# R7FA2E2A7 register map
Vendor: Renesas Electronics Corporation; Series: RA2; File version: 1.50.00
CPU: CM23 r1p0, little endian, MPU, no FPU, VTOR, 2 interrupt priority bits, 32 interrupts
Registers are 32-bit, read-write, reset 0x0 unless marked. A register's access mark holds for its fields unless they carry their own. Offsets are from the block's base; [hi:lo] are bit positions; {n}, {i} and the like mark numbered series; 'fields as' and 'values as' point back to an identical list.

## ELC — Event Link Controller
Base 0x40041000
0x00 ELCR 8-bit — Event Link Controller Register
  [7] ELCON — All Event Link Enable
    0=ELC function is disabled; 1=ELC function is enabled
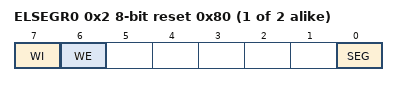
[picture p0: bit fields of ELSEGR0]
{0x2+2i} ELSEGR{i} (i=0..1) 8-bit reset 0x80 — Event Link Software Event Generation Register {i}
  [7] WI wo — ELSEGR Register Write Disable
    0=Write to ELSEGR register enabled; 1=Write to ELSEGR register disabled
  [6] WE — SEG Bit Write Enable
    0=Write to SEG bit disabled; 1=Write to SEG bit enabled
  [0] SEG wo — Software Event Generation
    0=Normal operation; 1=Software event is generated
{0x10+4i} ELSR{i} (i=0..3) 16-bit — Event Link Setting Register {i}
  [7:0] ELS — Event Link Select
{0x10+4i} ELSR{i} (i=8..9) 16-bit — Event Link Setting Register {i}
  [7:0] ELS — Event Link Select
{0x10+4i} ELSR{i} (i=14..15) 16-bit — Event Link Setting Register {i}
  [7:0] ELS — Event Link Select

## POEG — Port Output Enable Module for GPT
Base 0x40042000
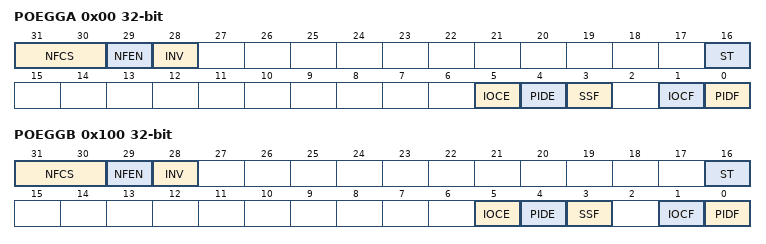
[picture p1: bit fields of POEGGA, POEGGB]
0x00 POEGGA — POEG Group A Setting Register
  [31:30] NFCS — Noise Filter Clock Select
    0=Sample GTETRGn pin input level three times every PCLKB; 1=Sample GTETRGn pin input level three times every PCLKB/8; 2=Sample GTETRGn pin input level three times every PCLKB/32; 3=Sample GTETRGn pin input level three times every PCLKB/128
  [29] NFEN — Noise Filter Enable
    0=Disable noise filtering; 1=Enable noise filtering
  [28] INV — GTETRGA Input Reverse
    0=Input GTETRGn as-is; 1=Input GTETRGn in reverse
  [16] ST ro — GTETRGA Input Status Flag
    0=GTETRGn input after filtering was 0; 1=GTETRGn input after filtering was 1
  [5] IOCE — Enable for GPT Output-Disable Request
    0=Disable output-disable requests from GPT; 1=Enable output-disable requests from GPT
  [4] PIDE — Port Input Detection Enable
    0=Disable output-disable requests from the GTETRGn pins; 1=Enable output-disable requests from the GTETRGn pins
  [3] SSF — Software Stop Flag
    0=No output-disable request from software occurred; 1=Output-disable request from software occurred
  [1] IOCF — Detection Flag for GPT Output-Disable Request
    0=No output-disable request from GPT occurred; 1=Output-disable request from GPT occurred
  [0] PIDF — Port Input Detection Flag
    0=No output-disable request from the GTETRGn pin occurred; 1=Output-disable request from the GTETRGn pin occurred
0x100 POEGGB — POEG Group B Setting Register
  [31:30] NFCS — Noise Filter Clock Select
    values as POEGGA.NFCS
  [29] NFEN — Noise Filter Enable
    0=Disable noise filtering; 1=Enable noise filtering
  [28] INV — GTETRGB Input Reverse
    0=Input GTETRGn as-is; 1=Input GTETRGn in reverse
  [16] ST ro — GTETRGB Input Status Flag
    values as POEGGA.ST
  [5] IOCE — Enable for GPT Output-Disable Request
    values as POEGGA.IOCE
  [4] PIDE — Port Input Detection Enable
    values as POEGGA.PIDE
  [3] SSF — Software Stop Flag
    values as POEGGA.SSF
  [1] IOCF — Detection Flag for GPT Output-Disable Request
    values as POEGGA.IOCF
  [0] PIDF — Port Input Detection Flag
    values as POEGGA.PIDF

## WDT — Watchdog Timer
Base 0x40044200
0x00 WDTRR 8-bit reset 0xFF — WDT Refresh Register
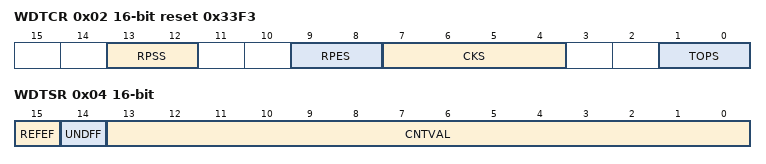
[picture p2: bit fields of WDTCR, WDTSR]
0x02 WDTCR 16-bit reset 0x33F3 — WDT Control Register
  [13:12] RPSS — Window Start Position Select
    0=25%; 1=50%; 2=75%; 3=100% (do not specify window start position)
  [9:8] RPES — Window End Position Select
    0=75%; 1=50%; 2=25%; 3=0% (do not specify window end position)
  [7:4] CKS — Clock Division Ratio Select
    1=PCLKB/4; 4=PCLKB/64; 15=PCLKB/128; 6=PCLKB/512; 7=PCLKB/2048; 8=PCLKB/8192; other=Others (Setting prohibited)
  [1:0] TOPS — Timeout Period Select
    0=1024 cycles (0x03FF); 1=4096 cycles (0x0FFF); 2=8192 cycles (0x1FFF); 3=16384 cycles (0x3FFF)
0x04 WDTSR 16-bit — WDT Status Register
  [15] REFEF — Refresh Error Flag
    0=No refresh error occurred; 1=Refresh error occurred
  [14] UNDFF — Underflow Flag
    0=No underflow occurred; 1=Underflow occurred
  [13:0] CNTVAL ro — Down-Counter Value
0x06 WDTRCR 8-bit reset 0x80 — WDT Reset Control Register
  [7] RSTIRQS — WDT Behavior Selection
    0=Interrupt; 1=Reset
0x08 WDTCSTPR 8-bit reset 0x80 — WDT Count Stop Control Register
  [7] SLCSTP — Sleep-Mode Count Stop Control Register
    0=Disable count stop; 1=Stop count on transition to Sleep mode

## Notices in the file
This software is supplied by Renesas Electronics Corporation and is only intended for
use with Renesas products. No other uses are authorized. This software is owned by
Renesas Electronics Corporation and is protected under all applicable laws, including
copyright laws.
THIS SOFTWARE IS PROVIDED "AS IS" AND RENESAS MAKES NO WARRANTIES REGARDING
THIS SOFTWARE, WHETHER EXPRESS, IMPLIED OR STATUTORY, INCLUDING BUT NOT LIMITED TO
WARRANTIES OF MERCHANTABILITY, FITNESS FOR A PARTICULAR PURPOSE AND NON-INFRINGEMENT.
ALL SUCH WARRANTIES ARE EXPRESSLY DISCLAIMED. TO THE MAXIMUM EXTENT PERMITTED NOT
PROHIBITED BY LAW, NEITHER RENESAS ELECTRONICS CORPORATION NOR ANY OF ITS AFFILIATED
COMPANIES SHALL BE LIABLE FOR ANY DIRECT, INDIRECT, SPECIAL, INCIDENTAL OR CONSEQUENTIAL
DAMAGES FOR ANY REASON RELATED TO THIS SOFTWARE, EVEN IF RENESAS OR ITS AFFILIATES HAVE
BEEN ADVISED OF THE POSSIBILITY OF SUCH DAMAGES.
Renesas reserves the right, without notice, to make changes to this software and to
discontinue the availability of this software. By using this software, you agree to
the additional terms and conditions found by accessing the following link:
http://www.renesas.com/disclaimer
